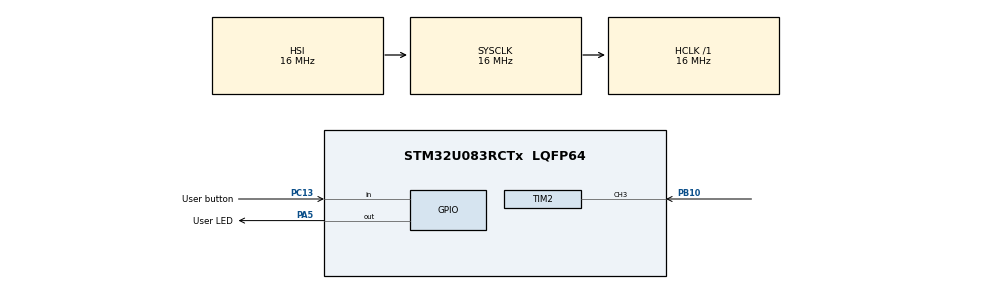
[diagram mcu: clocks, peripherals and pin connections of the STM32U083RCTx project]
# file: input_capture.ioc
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Mcu.Family=STM32U0
Mcu.Name=STM32U083RCTx
Mcu.Package=LQFP64
NVIC.PriorityGroup=NVIC_PRIORITYGROUP_2
NVIC.TIM2_IRQn=true\:0\:0\:false\:false\:true\:true\:true\:true
PA13\ (SWDIO).GPIO_Label=SWDIO
PA13\ (SWDIO).Signal=DEBUG_JTMS-SWDIO
PA14\ (SWCLK).GPIO_Label=SWCLK
PA14\ (SWCLK).Signal=DEBUG_JTCK-SWCLK
PA2.GPIO_Label=USART2_TX
PA2.Signal=USART2_TX
PA3.GPIO_Label=USART2_RX
PA3.Signal=USART2_RX
PA5.GPIO_Label=User LED
PA5.Signal=GPIO_Output
PB10.Signal=S_TIM2_CH3
PB8.GPIO_Label=I2C1_SCL
PB8.Signal=I2C1_SCL
PB9.GPIO_Label=I2C1_SDA
PB9.Signal=I2C1_SDA
PC13.GPIO_Label=User button
PC13.Signal=GPIO_Input
PC14-OSC32_IN.GPIO_Label=OSC32_IN
PC14-OSC32_IN.Signal=RCC_OSC32_IN
PC15-OSC32_OUT.GPIO_Label=OSC32_OUT
PC15-OSC32_OUT.Signal=RCC_OSC32_OUT
PF0-OSC_IN.GPIO_Label=OSC_IN
PF0-OSC_IN.Mode=HSE-External-Oscillator
PF0-OSC_IN.Signal=RCC_OSC_IN
PF1-OSC_OUT.GPIO_Label=OSC_OUT
PF1-OSC_OUT.Mode=HSE-External-Oscillator
PF1-OSC_OUT.Signal=RCC_OSC_OUT
ProjectManager.HeapSize=0x200
ProjectManager.StackSize=0x400
ProjectManager.TargetToolchain=STM32CubeIDE
RCC.AHBFreq_Value=16000000
RCC.CortexFreq_Value=16000000
RCC.HCLKFreq_Value=16000000
RCC.HSE_VALUE=4000000
RCC.HSI48_VALUE=48000000
RCC.HSI_VALUE=16000000
RCC.LSE_VALUE=32768
RCC.MSI_VALUE=4000000
RCC.SYSCLKFreq_VALUE=16000000
RCC.VCOOutputFreq_Value=64000000
SH.S_TIM2_CH3.0=TIM2_CH3,Input_Capture3_from_TI3
TIM2.Channel-Input_Capture3_from_TI3=TIM_CHANNEL_3
TIM2.Prescaler=15
VP_PWR_VS_SECSignals.Mode=Security/Privilege
VP_TIM2_VS_ClockSourceINT.Mode=Internal
board=NUCLEO-U083RC

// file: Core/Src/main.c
/* USER CODE BEGIN Header */
/**
  ******************************************************************************
  * @file           : main.c
  * @brief          : Main program body
  ******************************************************************************
  * @attention
  *
  * Copyright (c) 2026 STMicroelectronics.
  * All rights reserved.
  *
  * This software is licensed under terms that can be found in the LICENSE file
  * in the root directory of this software component.
  * If no LICENSE file comes with this software, it is provided AS-IS.
  *
  ******************************************************************************
  */
/* USER CODE END Header */
#include "main.h"

TIM_HandleTypeDef htim2;

/* USER CODE BEGIN PV */
volatile uint32_t diff = 0;
volatile float frequency = 0;
/* USER CODE END PV */

void SystemClock_Config(void);
static void MX_GPIO_Init(void);
static void MX_TIM2_Init(void);

/* USER CODE BEGIN 0 */
void HAL_TIM_IC_CaptureCallback(TIM_HandleTypeDef *htim)
{
    if (htim->Instance == TIM2 && htim->Channel == HAL_TIM_ACTIVE_CHANNEL_3)
    {
        static uint32_t last_val = 0;
        uint32_t current_val = HAL_TIM_ReadCapturedValue(htim, TIM_CHANNEL_3);

        if (current_val >= last_val) {
            diff = current_val - last_val;
        } else {
            diff = (0xFFFFFFFF - last_val) + current_val + 1;
        }

        if (diff != 0) {
            // ใช้ 4000000.0f หากพิสูจน์แล้วว่าบอร์ดวิ่ง 64MHz
            frequency = 1000000.0f / (float)diff;
        }

        last_val = current_val;
        HAL_GPIO_TogglePin(User_LED_GPIO_Port, User_LED_Pin);
    }
}
/* USER CODE END 0 */

int main(void)
{

  /* MCU Configuration--------------------------------------------------------*/

  /* Reset of all peripherals, Initializes the Flash interface and the Systick. */
  HAL_Init();

  /* Configure the system clock */
  SystemClock_Config();

  /* Initialize all configured peripherals */
  MX_GPIO_Init();
  MX_TIM2_Init();
  /* USER CODE BEGIN 2 */
  HAL_TIM_IC_Start_IT(&htim2, TIM_CHANNEL_3);
  /* USER CODE END 2 */

  /* Infinite loop */
  while (1)
  {

  }
}

void SystemClock_Config(void)
{
  RCC_OscInitTypeDef RCC_OscInitStruct = {0};
  RCC_ClkInitTypeDef RCC_ClkInitStruct = {0};

  /** Configure the main internal regulator output voltage
  */
  HAL_PWREx_ControlVoltageScaling(PWR_REGULATOR_VOLTAGE_SCALE2);

  /** Initializes the RCC Oscillators according to the specified parameters
  * in the RCC_OscInitTypeDef structure.
  */
  RCC_OscInitStruct.OscillatorType = RCC_OSCILLATORTYPE_HSI;
  RCC_OscInitStruct.HSIState = RCC_HSI_ON;
  RCC_OscInitStruct.HSICalibrationValue = RCC_HSICALIBRATION_DEFAULT;
  RCC_OscInitStruct.PLL.PLLState = RCC_PLL_NONE;
  if (HAL_RCC_OscConfig(&RCC_OscInitStruct) != HAL_OK)
  {
    Error_Handler();
  }

  /** Initializes the CPU, AHB and APB buses clocks
  */
  RCC_ClkInitStruct.ClockType = RCC_CLOCKTYPE_HCLK|RCC_CLOCKTYPE_SYSCLK
                              |RCC_CLOCKTYPE_PCLK1;
  RCC_ClkInitStruct.SYSCLKSource = RCC_SYSCLKSOURCE_HSI;
  RCC_ClkInitStruct.AHBCLKDivider = RCC_SYSCLK_DIV1;
  RCC_ClkInitStruct.APB1CLKDivider = RCC_HCLK_DIV1;

  if (HAL_RCC_ClockConfig(&RCC_ClkInitStruct, FLASH_LATENCY_1) != HAL_OK)
  {
    Error_Handler();
  }
}

static void MX_TIM2_Init(void)
{

  TIM_ClockConfigTypeDef sClockSourceConfig = {0};
  TIM_MasterConfigTypeDef sMasterConfig = {0};
  TIM_IC_InitTypeDef sConfigIC = {0};

  htim2.Instance = TIM2;
  htim2.Init.Prescaler = 15;
  htim2.Init.CounterMode = TIM_COUNTERMODE_UP;
  htim2.Init.Period = 4294967295;
  htim2.Init.ClockDivision = TIM_CLOCKDIVISION_DIV1;
  htim2.Init.AutoReloadPreload = TIM_AUTORELOAD_PRELOAD_DISABLE;
  if (HAL_TIM_Base_Init(&htim2) != HAL_OK)
  {
    Error_Handler();
  }
  sClockSourceConfig.ClockSource = TIM_CLOCKSOURCE_INTERNAL;
  if (HAL_TIM_ConfigClockSource(&htim2, &sClockSourceConfig) != HAL_OK)
  {
    Error_Handler();
  }
  if (HAL_TIM_IC_Init(&htim2) != HAL_OK)
  {
    Error_Handler();
  }
  sMasterConfig.MasterOutputTrigger = TIM_TRGO_RESET;
  sMasterConfig.MasterSlaveMode = TIM_MASTERSLAVEMODE_DISABLE;
  if (HAL_TIMEx_MasterConfigSynchronization(&htim2, &sMasterConfig) != HAL_OK)
  {
    Error_Handler();
  }
  sConfigIC.ICPolarity = TIM_INPUTCHANNELPOLARITY_RISING;
  sConfigIC.ICSelection = TIM_ICSELECTION_DIRECTTI;
  sConfigIC.ICPrescaler = TIM_ICPSC_DIV1;
  sConfigIC.ICFilter = 0;
  if (HAL_TIM_IC_ConfigChannel(&htim2, &sConfigIC, TIM_CHANNEL_3) != HAL_OK)
  {
    Error_Handler();
  }

}

static void MX_GPIO_Init(void)
{
  GPIO_InitTypeDef GPIO_InitStruct = {0};

  /* GPIO Ports Clock Enable */
  __HAL_RCC_GPIOC_CLK_ENABLE();
  __HAL_RCC_GPIOF_CLK_ENABLE();
  __HAL_RCC_GPIOA_CLK_ENABLE();
  __HAL_RCC_GPIOB_CLK_ENABLE();

  /*Configure GPIO pin Output Level */
  HAL_GPIO_WritePin(User_LED_GPIO_Port, User_LED_Pin, GPIO_PIN_RESET);

  /*Configure GPIO pin : User_button_Pin */
  GPIO_InitStruct.Pin = User_button_Pin;
  GPIO_InitStruct.Mode = GPIO_MODE_INPUT;
  GPIO_InitStruct.Pull = GPIO_NOPULL;
  HAL_GPIO_Init(User_button_GPIO_Port, &GPIO_InitStruct);

  /*Configure GPIO pins : USART2_TX_Pin USART2_RX_Pin */
  GPIO_InitStruct.Pin = USART2_TX_Pin|USART2_RX_Pin;
  GPIO_InitStruct.Mode = GPIO_MODE_AF_PP;
  GPIO_InitStruct.Pull = GPIO_NOPULL;
  GPIO_InitStruct.Speed = GPIO_SPEED_FREQ_LOW;
  GPIO_InitStruct.Alternate = GPIO_AF7_USART2;
  HAL_GPIO_Init(GPIOA, &GPIO_InitStruct);

  /*Configure GPIO pin : User_LED_Pin */
  GPIO_InitStruct.Pin = User_LED_Pin;
  GPIO_InitStruct.Mode = GPIO_MODE_OUTPUT_PP;
  GPIO_InitStruct.Pull = GPIO_NOPULL;
  GPIO_InitStruct.Speed = GPIO_SPEED_FREQ_LOW;
  HAL_GPIO_Init(User_LED_GPIO_Port, &GPIO_InitStruct);

  /*Configure GPIO pins : I2C1_SCL_Pin I2C1_SDA_Pin */
  GPIO_InitStruct.Pin = I2C1_SCL_Pin|I2C1_SDA_Pin;
  GPIO_InitStruct.Mode = GPIO_MODE_AF_OD;
  GPIO_InitStruct.Pull = GPIO_NOPULL;
  GPIO_InitStruct.Speed = GPIO_SPEED_FREQ_LOW;
  GPIO_InitStruct.Alternate = GPIO_AF4_I2C1;
  HAL_GPIO_Init(GPIOB, &GPIO_InitStruct);

}

void Error_Handler(void)
{
  __disable_irq();
  while (1)
  {
  }
}
